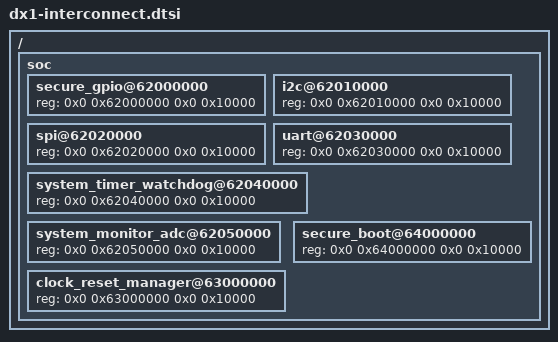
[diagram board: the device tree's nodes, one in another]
/* Auto-generated. */
/ {
  soc {
    secure_gpio@62000000 { reg = <0x0 0x62000000 0x0 0x10000>; };
    i2c@62010000 { reg = <0x0 0x62010000 0x0 0x10000>; };
    spi@62020000 { reg = <0x0 0x62020000 0x0 0x10000>; };
    uart@62030000 { reg = <0x0 0x62030000 0x0 0x10000>; };
    system_timer_watchdog@62040000 { reg = <0x0 0x62040000 0x0 0x10000>; };
    system_monitor_adc@62050000 { reg = <0x0 0x62050000 0x0 0x10000>; };
    clock_reset_manager@63000000 { reg = <0x0 0x63000000 0x0 0x10000>; };
    secure_boot@64000000 { reg = <0x0 0x64000000 0x0 0x10000>; };
  };
};
